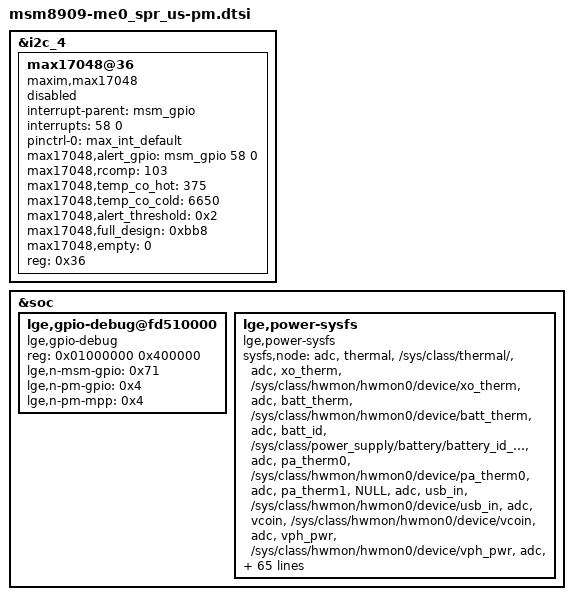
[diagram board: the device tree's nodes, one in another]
/* Copyright (c) 2014, The Linux Foundation. All rights reserved.
 *
 * This program is free software; you can redistribute it and/or modify
 * it under the terms of the GNU General Public License version 2 and
 * only version 2 as published by the Free Software Foundation.
 *
 * This program is distributed in the hope that it will be useful,
 * but WITHOUT ANY WARRANTY; without even the implied warranty of
 * MERCHANTABILITY or FITNESS FOR A PARTICULAR PURPOSE.  See the
 * GNU General Public License for more details.
 */

&i2c_4 {
	/* BLSP1 QUP4 */
	max17048@36 {
		status = "disabled";
		compatible = "maxim,max17048";
		interrupt-parent = <&msm_gpio>;
		interrupts = <58 0>;
		pinctrl-names = "default";
		pinctrl-0 = <&max_int_default>;
		max17048,alert_gpio = <&msm_gpio 58 0>;
		max17048,rcomp = <103>;
		max17048,temp_co_hot = <375>;
		max17048,temp_co_cold = <6650>;
		max17048,alert_threshold = <0x2>;
		max17048,full_design = <0xbb8>;
		max17048,empty = <0>;
		reg = <0x36>;
	};
};

&soc {
	lge,gpio-debug@fd510000 {
		compatible = "lge,gpio-debug";
		reg = <0x01000000 0x400000>;
		reg-names = "tlmm-base";
		lge,n-msm-gpio = <0x71>;
		lge,n-pm-gpio = <0x4>;
		lge,n-pm-mpp = <0x4>;
	};
};

&soc {
	lge,power-sysfs {
		compatible = "lge,power-sysfs";

		sysfs,node =
			/* group , user_node,  kernel node */
			/* ADC/MPP */
			"adc", "thermal", "/sys/class/thermal/",
			"adc", "xo_therm", "/sys/class/hwmon/hwmon0/device/xo_therm",
			"adc", "batt_therm", "/sys/class/hwmon/hwmon0/device/batt_therm",
			"adc", "batt_id", "/sys/class/power_supply/battery/battery_id_checker",
			"adc", "pa_therm0", "/sys/class/hwmon/hwmon0/device/pa_therm0",
			"adc", "pa_therm1", "NULL",
			"adc", "usb_in", "/sys/class/hwmon/hwmon0/device/usb_in",
			"adc", "vcoin", "/sys/class/hwmon/hwmon0/device/vcoin",
			"adc", "vph_pwr", "/sys/class/hwmon/hwmon0/device/vph_pwr",
			"adc", "usb_id", "/sys/class/hwmon/hwmon0/device/usb_id",
			/* Battery */
			"battery", "capacity", "/sys/class/power_supply/battery/capacity",
			"battery", "health", "/sys/class/power_supply/battery/health",
			"battery", "present", "/sys/class/power_supply/battery/present",
			"battery", "pseudo_batt", "/sys/class/power_supply/battery/pseudo_batt",
			"battery", "status", "/sys/class/power_supply/battery/status",
			"battery", "temp", "/sys/class/power_supply/battery/temp",
			"battery", "valid_batt_id", "/sys/class/power_supply/battery/valid_batt_id",
			"battery", "voltage_now", "/sys/class/power_supply/battery/voltage_now",
			/* Charger */
			"charger", "ac_online", "NULL",
			"charger", "usb_online", "/sys/class/power_supply/usb/online",
			"charger", "present", "/sys/class/power_supply/usb/present",
			"charger", "wlc_online", "NULL",
			"charger", "type", "/sys/class/power_supply/usb/type",
			"charger", "time_out", "NULL",
			"charger", "charging_enabled", "/sys/class/power_supply/battery/charging_enabled",
			"charger", "ibat_current", "/sys/class/power_supply/battery/current_now",
			"charger", "ichg_current", "/sys/class/power_supply/usb/current_max",
			"charger", "iusb_control", "NULL",
			"charger", "thermal_mitigation", "/sys/module/qpnp_linear_charger/parameters/qpnp_thermal_mitigation",
			"charger", "wlc_thermal_mitigation", "NULL",
			"charger", "usb_parallel_chg_status", "NULL",
			"charger", "usb_parallel_charging_enabled", "NULL",
			/* LCD Backlight */
			"lcd", "brightness", "/sys/class/leds/lcd-backlight/brightness",
			"lcd", "max_brightness", "/sys/class/leds/lcd-backlight/max_brightness",
			/* KEY LED */
			"key_led", "red_brightness", "/sys/class/leds/R/brightness",
			"key_led", "green_brightness", "/sys/class/leds/G/brightness",
			"key_led", "blue_brightness", "/sys/class/leds/B/brightness",
			/* CPU */
			"cpu", "cpu_idle_modes", "NULL",
			/* GPU */
			"gpu", "busy", "/sys/class/kgsl/kgsl-3d0/gpubusy",
			/* PLATFORM */
			"platform", "speed_bin", "NULL",
			"platform", "pvs_bin", "NULL",
			"platform", "power_state", "/sys/power/autosleep",
			"platform", "poweron_alarm", "/sys/module/qpnp_rtc/parameters/poweron_alarm",
			"platform", "pcb_rev", "/sys/class/hwmon/hwmon0/device/pcb_rev",
			/* testmode */
			"testmode", "charge", "/sys/class/power_supply/battery/device/at_charge",
			"testmode", "chcomp", "/sys/class/power_supply/battery/device/at_chcomp",
			"testmode", "chgmodeoff", "/sys/class/power_supply/battery/charging_enabled",
			"testmode", "fuelrst", "NULL",
			"testmode", "rtc_time", "/dev/rtc0",
			"testmode", "pmrst", "NULL",
			"testmode", "battexit", "/sys/class/power_supply/battery/present"
			;
	};
};
